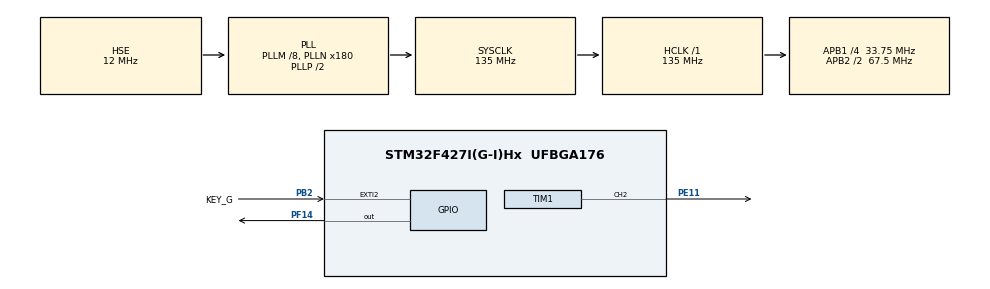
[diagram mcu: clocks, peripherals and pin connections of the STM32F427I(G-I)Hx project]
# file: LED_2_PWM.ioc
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Mcu.Family=STM32F4
Mcu.Name=STM32F427I(G-I)Hx
Mcu.Package=UFBGA176
NVIC.EXTI2_IRQn=true\:0\:0\:false\:false\:true\:true\:true\:true
NVIC.PriorityGroup=NVIC_PRIORITYGROUP_4
NVIC.TIM1_UP_TIM10_IRQn=true\:0\:0\:false\:false\:true\:true\:true\:true
NVIC.TIM8_UP_TIM13_IRQn=true\:0\:0\:false\:false\:true\:true\:true\:true
PA13.Mode=Serial_Wire
PA13.Signal=SYS_JTMS-SWDIO
PA14.Mode=Serial_Wire
PA14.Signal=SYS_JTCK-SWCLK
PB2/BOOT1.GPIO_Label=KEY_G
PB2/BOOT1.GPIO_ModeDefaultEXTI=GPIO_MODE_IT_RISING
PB2/BOOT1.Signal=GPXTI2
PE11.Signal=S_TIM1_CH2
PF14.Signal=GPIO_Output
PH0/OSC_IN.Mode=HSE-External-Oscillator
PH0/OSC_IN.Signal=RCC_OSC_IN
PH1/OSC_OUT.Mode=HSE-External-Oscillator
PH1/OSC_OUT.Signal=RCC_OSC_OUT
ProjectManager.HeapSize=0x200
ProjectManager.StackSize=0x400
ProjectManager.TargetToolchain=MDK-ARM V5.32
RCC.48MHZClocksFreq_Value=67500000
RCC.AHBFreq_Value=135000000
RCC.APB1CLKDivider=RCC_HCLK_DIV4
RCC.APB1Freq_Value=33750000
RCC.APB1TimFreq_Value=67500000
RCC.APB2CLKDivider=RCC_HCLK_DIV2
RCC.APB2Freq_Value=67500000
RCC.APB2TimFreq_Value=135000000
RCC.CortexFreq_Value=135000000
RCC.HCLKFreq_Value=135000000
RCC.HSE_VALUE=12000000
RCC.HSI_VALUE=16000000
RCC.LSE_VALUE=32768
RCC.PLLM=8
RCC.PLLN=180
RCC.PLLSourceVirtual=RCC_PLLSOURCE_HSE
RCC.SYSCLKFreq_VALUE=135000000
RCC.SYSCLKSource=RCC_SYSCLKSOURCE_PLLCLK
RCC.VCOOutputFreq_Value=270000000
SH.S_TIM1_CH2.0=TIM1_CH2,PWM Generation2 CH2
TIM1.Channel-PWM\ Generation2\ CH2=TIM_CHANNEL_2
TIM1.Period=9999
TIM1.Prescaler=17999
TIM1.Pulse-PWM\ Generation2\ CH2=5000
TIM8.Period=9999
TIM8.Prescaler=1799
VP_TIM1_VS_ClockSourceINT.Mode=Internal
VP_TIM8_VS_ClockSourceINT.Mode=Internal
board=custom

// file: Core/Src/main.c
/* USER CODE BEGIN Header */
/**
  ******************************************************************************
  * @file           : main.c
  * @brief          : Main program body
  ******************************************************************************
  * @attention
  *
  * Copyright (c) 2024 STMicroelectronics.
  * All rights reserved.
  *
  * This software is licensed under terms that can be found in the LICENSE file
  * in the root directory of this software component.
  * If no LICENSE file comes with this software, it is provided AS-IS.
  *
  ******************************************************************************
  */
/* USER CODE END Header */
#include "main.h"
#include "tim.h"
#include "gpio.h"
int PWM_FLAG=0;

void SystemClock_Config(void);

int main(void)
{

  /* MCU Configuration--------------------------------------------------------*/

  /* Reset of all peripherals, Initializes the Flash interface and the Systick. */
  HAL_Init();

  /* Configure the system clock */
  SystemClock_Config();

  /* Initialize all configured peripherals */
  MX_GPIO_Init();
  MX_TIM1_Init();
  MX_TIM8_Init();
  /* USER CODE BEGIN 2 */
	HAL_TIM_Base_Start_IT(&htim1);
  //HAL_TIM_Base_Start_IT(&htim8);
  HAL_TIM_PWM_Start_IT(&htim1, TIM_CHANNEL_2);
  /* USER CODE END 2 */

  /* Infinite loop */
  while (1)
  {

  }
}

void SystemClock_Config(void)
{
  RCC_OscInitTypeDef RCC_OscInitStruct = {0};
  RCC_ClkInitTypeDef RCC_ClkInitStruct = {0};

  /** Configure the main internal regulator output voltage
  */
  __HAL_RCC_PWR_CLK_ENABLE();
  __HAL_PWR_VOLTAGESCALING_CONFIG(PWR_REGULATOR_VOLTAGE_SCALE2);

  /** Initializes the RCC Oscillators according to the specified parameters
  * in the RCC_OscInitTypeDef structure.
  */
  RCC_OscInitStruct.OscillatorType = RCC_OSCILLATORTYPE_HSE;
  RCC_OscInitStruct.HSEState = RCC_HSE_ON;
  RCC_OscInitStruct.PLL.PLLState = RCC_PLL_ON;
  RCC_OscInitStruct.PLL.PLLSource = RCC_PLLSOURCE_HSE;
  RCC_OscInitStruct.PLL.PLLM = 8;
  RCC_OscInitStruct.PLL.PLLN = 180;
  RCC_OscInitStruct.PLL.PLLP = RCC_PLLP_DIV2;
  RCC_OscInitStruct.PLL.PLLQ = 4;
  if (HAL_RCC_OscConfig(&RCC_OscInitStruct) != HAL_OK)
  {
    Error_Handler();
  }

  /** Initializes the CPU, AHB and APB buses clocks
  */
  RCC_ClkInitStruct.ClockType = RCC_CLOCKTYPE_HCLK|RCC_CLOCKTYPE_SYSCLK
                              |RCC_CLOCKTYPE_PCLK1|RCC_CLOCKTYPE_PCLK2;
  RCC_ClkInitStruct.SYSCLKSource = RCC_SYSCLKSOURCE_PLLCLK;
  RCC_ClkInitStruct.AHBCLKDivider = RCC_SYSCLK_DIV1;
  RCC_ClkInitStruct.APB1CLKDivider = RCC_HCLK_DIV4;
  RCC_ClkInitStruct.APB2CLKDivider = RCC_HCLK_DIV2;

  if (HAL_RCC_ClockConfig(&RCC_ClkInitStruct, FLASH_LATENCY_4) != HAL_OK)
  {
    Error_Handler();
  }
}

void Error_Handler(void)
{
  __disable_irq();
  while (1)
  {
  }
}
